VERSION ""

NS_ :

BS_:

BU_: tx_node
VAL_TABLE_ example_choice 255 "Not available" 254 "Error" ;

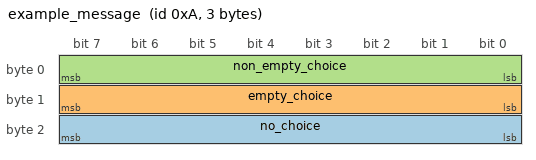
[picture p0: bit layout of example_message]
BO_ 10 example_message: 3 tx_node
 SG_ no_choice : 16|8@1- (1,0) [0|0] "" Vector__XXX
 SG_ empty_choice : 8|8@1- (1,0) [0|0] "" Vector__XXX
 SG_ non_empty_choice : 0|8@1- (1,0) [0|0] "" Vector__XXX

BA_DEF_  "BusType" STRING ;
BA_DEF_DEF_  "BusType" "CAN";
VAL_ 10 non_empty_choice 255 "Not available" 254 "Error" ;
